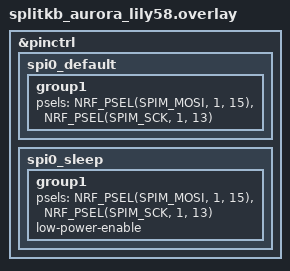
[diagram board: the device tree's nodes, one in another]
#include <dt-bindings/pinctrl/nrf-pinctrl.h>

&pinctrl {
    spi0_default: spi0_default {
        group1 {
            psels = <NRF_PSEL(SPIM_MOSI, 1, 15)>,
                    <NRF_PSEL(SPIM_SCK, 1, 13)>;
        };
    };
    spi0_sleep: spi0_sleep {
        group1 {
            psels = <NRF_PSEL(SPIM_MOSI, 1, 15)>,
                    <NRF_PSEL(SPIM_SCK, 1, 13)>;
            low-power-enable;
        };
    };
};
